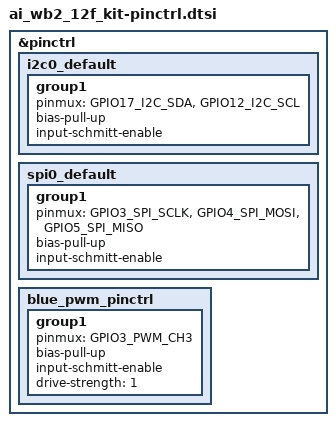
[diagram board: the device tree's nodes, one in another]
/*
 * Copyright (c) 2024-2025 MASSDRIVER EI (massdriver.space)
 *
 * SPDX-License-Identifier: Apache-2.0
 */

&pinctrl {
	i2c0_default: i2c0_default {
		group1 {
			pinmux = <GPIO17_I2C_SDA>,
				 <GPIO12_I2C_SCL>;
			bias-pull-up;
			input-schmitt-enable;
		};
	};

	spi0_default: spi0_default {
		group1 {
			pinmux = <GPIO3_SPI_SCLK>,
				 <GPIO4_SPI_MOSI>,
				 <GPIO5_SPI_MISO>;
			bias-pull-up;
			input-schmitt-enable;
		};
	};

	blue_pwm_pinctrl: blue_pwm_pinctrl {
		group1 {
			pinmux = <GPIO3_PWM_CH3>;
			bias-pull-up;
			input-schmitt-enable;
			drive-strength = <1>;
		};
	};
};
